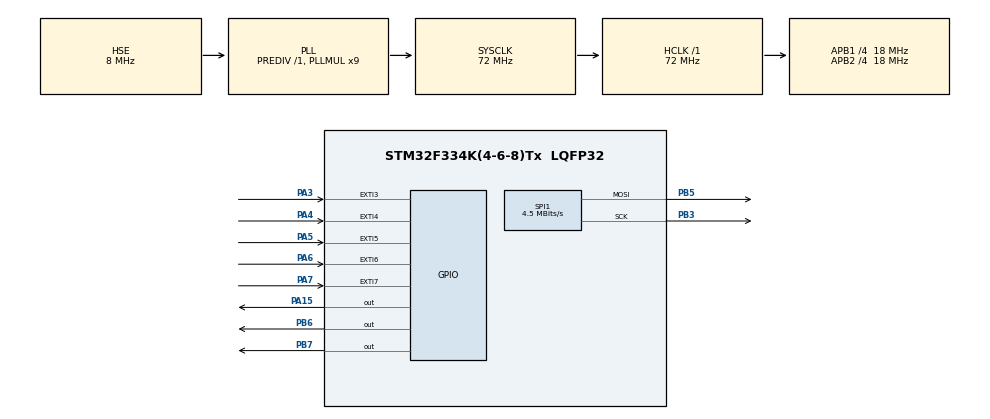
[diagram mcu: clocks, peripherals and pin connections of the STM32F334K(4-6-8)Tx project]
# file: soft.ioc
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Dma.Request0=SPI1_TX
Dma.SPI1_TX.0.Direction=DMA_MEMORY_TO_PERIPH
Dma.SPI1_TX.0.Instance=DMA1_Channel3
Dma.SPI1_TX.0.MemDataAlignment=DMA_MDATAALIGN_BYTE
Dma.SPI1_TX.0.MemInc=DMA_MINC_ENABLE
Dma.SPI1_TX.0.Mode=DMA_NORMAL
Dma.SPI1_TX.0.PeriphDataAlignment=DMA_PDATAALIGN_BYTE
Dma.SPI1_TX.0.PeriphInc=DMA_PINC_DISABLE
Dma.SPI1_TX.0.Priority=DMA_PRIORITY_LOW
Mcu.Family=STM32F3
Mcu.Name=STM32F334K(4-6-8)Tx
Mcu.Package=LQFP32
NVIC.DMA1_Channel3_IRQn=true\:0\:0\:false\:false\:true
NVIC.EXTI3_IRQn=true\:0\:0\:false\:false\:true
NVIC.EXTI4_IRQn=true\:0\:0\:false\:false\:true
NVIC.EXTI9_5_IRQn=true\:0\:0\:false\:false\:true
NVIC.PriorityGroup=NVIC_PRIORITYGROUP_4
NVIC.RTC_WKUP_IRQn=true\:0\:0\:false\:false\:true
PA13.Mode=Serial_Wire
PA13.Signal=SYS_JTMS-SWDIO
PA14.Mode=Serial_Wire
PA14.Signal=SYS_JTCK-SWCLK
PA15.Signal=GPIO_Output
PA3.GPIO_ModeDefaultEXTI=GPIO_MODE_IT_RISING
PA3.GPIO_PuPd=GPIO_PULLDOWN
PA3.Signal=GPXTI3
PA4.GPIO_ModeDefaultEXTI=GPIO_MODE_IT_RISING
PA4.GPIO_PuPd=GPIO_PULLDOWN
PA4.Signal=GPXTI4
PA5.GPIO_ModeDefaultEXTI=GPIO_MODE_IT_RISING
PA5.GPIO_PuPd=GPIO_PULLDOWN
PA5.Signal=GPXTI5
PA6.GPIO_ModeDefaultEXTI=GPIO_MODE_IT_RISING
PA6.GPIO_PuPd=GPIO_PULLDOWN
PA6.Signal=GPXTI6
PA7.GPIO_ModeDefaultEXTI=GPIO_MODE_IT_RISING
PA7.GPIO_PuPd=GPIO_PULLDOWN
PA7.Signal=GPXTI7
PB3.Mode=TX_Only_Simplex_Unidirect_Master
PB3.Signal=SPI1_SCK
PB4.Signal=SPI1_MISO
PB5.Mode=TX_Only_Simplex_Unidirect_Master
PB5.Signal=SPI1_MOSI
PB6.Signal=GPIO_Output
PB7.Signal=GPIO_Output
PF0\ /\ OSC_IN.Mode=HSE-External-Oscillator
PF0\ /\ OSC_IN.Signal=RCC_OSC_IN
PF1\ /\ OSC_OUT.Mode=HSE-External-Oscillator
PF1\ /\ OSC_OUT.Signal=RCC_OSC_OUT
ProjectManager.HeapSize=0x200
ProjectManager.StackSize=0x400
ProjectManager.TargetToolchain=TrueSTUDIO
RCC.AHBFreq_Value=72000000
RCC.APB1CLKDivider=RCC_HCLK_DIV4
RCC.APB1Freq_Value=18000000
RCC.APB1TimFreq_Value=36000000
RCC.APB2CLKDivider=RCC_HCLK_DIV4
RCC.APB2Freq_Value=18000000
RCC.APB2TimFreq_Value=36000000
RCC.CortexFreq_Value=72000000
RCC.HCLKFreq_Value=72000000
RCC.HSE_VALUE=8000000
RCC.HSIState=RCC_HSI_ON
RCC.HSI_VALUE=8000000
RCC.PLLMUL=RCC_PLL_MUL9
RCC.PLLSourceVirtual=RCC_PLLSOURCE_HSE
RCC.SYSCLKFreq_VALUE=72000000
RCC.SYSCLKSourceVirtual=RCC_SYSCLKSOURCE_PLLCLK
RCC.VDD_VALUE=3
RTC.WakeUpCounter=12500
SPI1.BaudRatePrescaler=SPI_BAUDRATEPRESCALER_4
SPI1.CLKPhase=SPI_PHASE_1EDGE
SPI1.CRCCalculation=SPI_CRCCALCULATION_DISABLE
SPI1.CalculateBaudRate=4.5 MBits/s
SPI1.DataSize=SPI_DATASIZE_8BIT
SPI1.Mode=SPI_MODE_MASTER
VP_RTC_VS_RTC_Activate.Mode=RTC_Enabled
VP_RTC_VS_RTC_Calendar.Mode=RTC_Calendar
VP_RTC_VS_RTC_WakeUp_intern.Mode=WakeUp
board=soft

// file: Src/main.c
/**
  ******************************************************************************
  * File Name          : main.c
  * Description        : Main program body
  ******************************************************************************
  *
  * COPYRIGHT(c) 2017 STMicroelectronics
  *
  * Redistribution and use in source and binary forms, with or without modification,
  * are permitted provided that the following conditions are met:
  *   1. Redistributions of source code must retain the above copyright notice,
  *      this list of conditions and the following disclaimer.
  *   2. Redistributions in binary form must reproduce the above copyright notice,
  *      this list of conditions and the following disclaimer in the documentation
  *      and/or other materials provided with the distribution.
  *   3. Neither the name of STMicroelectronics nor the names of its contributors
  *      may be used to endorse or promote products derived from this software
  *      without specific prior written permission.
  *
  * THIS SOFTWARE IS PROVIDED BY THE COPYRIGHT HOLDERS AND CONTRIBUTORS "AS IS"
  * AND ANY EXPRESS OR IMPLIED WARRANTIES, INCLUDING, BUT NOT LIMITED TO, THE
  * IMPLIED WARRANTIES OF MERCHANTABILITY AND FITNESS FOR A PARTICULAR PURPOSE ARE
  * DISCLAIMED. IN NO EVENT SHALL THE COPYRIGHT HOLDER OR CONTRIBUTORS BE LIABLE
  * FOR ANY DIRECT, INDIRECT, INCIDENTAL, SPECIAL, EXEMPLARY, OR CONSEQUENTIAL
  * DAMAGES (INCLUDING, BUT NOT LIMITED TO, PROCUREMENT OF SUBSTITUTE GOODS OR
  * SERVICES; LOSS OF USE, DATA, OR PROFITS; OR BUSINESS INTERRUPTION) HOWEVER
  * CAUSED AND ON ANY THEORY OF LIABILITY, WHETHER IN CONTRACT, STRICT LIABILITY,
  * OR TORT (INCLUDING NEGLIGENCE OR OTHERWISE) ARISING IN ANY WAY OUT OF THE USE
  * OF THIS SOFTWARE, EVEN IF ADVISED OF THE POSSIBILITY OF SUCH DAMAGE.
  *
  ******************************************************************************
  */
#include "main.h"
#include "stm32f3xx_hal.h"
#include "dma.h"
#include "rtc.h"
#include "spi.h"
#include "gpio.h"

/* USER CODE BEGIN Includes */
#include "exec.h"
/* USER CODE END Includes */

/* USER CODE BEGIN PV */
/* Private variables ---------------------------------------------------------*/

/* USER CODE END PV */

void SystemClock_Config(void);
void Error_Handler(void);

/* USER CODE BEGIN PFP */
/* Private function prototypes -----------------------------------------------*/

/* USER CODE END PFP */

int main(void)
{

  /* MCU Configuration----------------------------------------------------------*/

  /* Reset of all peripherals, Initializes the Flash interface and the Systick. */
  HAL_Init();

  /* Configure the system clock */
  SystemClock_Config();

  /* Initialize all configured peripherals */
  MX_GPIO_Init();
  MX_DMA_Init();
  MX_SPI1_Init();
  MX_RTC_Init();

  /* Infinite loop */
  while (1)
  {

  /* USER CODE BEGIN 3 */
	  exec();
  }
  /* USER CODE END 3 */

}

/** System Clock Configuration
*/
void SystemClock_Config(void)
{

  RCC_OscInitTypeDef RCC_OscInitStruct;
  RCC_ClkInitTypeDef RCC_ClkInitStruct;
  RCC_PeriphCLKInitTypeDef PeriphClkInit;

    /**Initializes the CPU, AHB and APB busses clocks
    */
  RCC_OscInitStruct.OscillatorType = RCC_OSCILLATORTYPE_LSI|RCC_OSCILLATORTYPE_HSE;
  RCC_OscInitStruct.HSEState = RCC_HSE_ON;
  RCC_OscInitStruct.HSEPredivValue = RCC_HSE_PREDIV_DIV1;
  RCC_OscInitStruct.HSIState = RCC_HSI_ON;
  RCC_OscInitStruct.LSIState = RCC_LSI_ON;
  RCC_OscInitStruct.PLL.PLLState = RCC_PLL_ON;
  RCC_OscInitStruct.PLL.PLLSource = RCC_PLLSOURCE_HSE;
  RCC_OscInitStruct.PLL.PLLMUL = RCC_PLL_MUL9;
  if (HAL_RCC_OscConfig(&RCC_OscInitStruct) != HAL_OK)
  {
    Error_Handler();
  }

    /**Initializes the CPU, AHB and APB busses clocks
    */
  RCC_ClkInitStruct.ClockType = RCC_CLOCKTYPE_HCLK|RCC_CLOCKTYPE_SYSCLK
                              |RCC_CLOCKTYPE_PCLK1|RCC_CLOCKTYPE_PCLK2;
  RCC_ClkInitStruct.SYSCLKSource = RCC_SYSCLKSOURCE_PLLCLK;
  RCC_ClkInitStruct.AHBCLKDivider = RCC_SYSCLK_DIV1;
  RCC_ClkInitStruct.APB1CLKDivider = RCC_HCLK_DIV4;
  RCC_ClkInitStruct.APB2CLKDivider = RCC_HCLK_DIV4;

  if (HAL_RCC_ClockConfig(&RCC_ClkInitStruct, FLASH_LATENCY_2) != HAL_OK)
  {
    Error_Handler();
  }

  PeriphClkInit.PeriphClockSelection = RCC_PERIPHCLK_RTC;
  PeriphClkInit.RTCClockSelection = RCC_RTCCLKSOURCE_LSI;
  if (HAL_RCCEx_PeriphCLKConfig(&PeriphClkInit) != HAL_OK)
  {
    Error_Handler();
  }

    /**Configure the Systick interrupt time
    */
  HAL_SYSTICK_Config(HAL_RCC_GetHCLKFreq()/1000);

    /**Configure the Systick
    */
  HAL_SYSTICK_CLKSourceConfig(SYSTICK_CLKSOURCE_HCLK);

  /* SysTick_IRQn interrupt configuration */
  HAL_NVIC_SetPriority(SysTick_IRQn, 0, 0);
}

void Error_Handler(void)
{
  while(1)
  {
  }
}

/************************ (C) COPYRIGHT STMicroelectronics *****END OF FILE****/
